# iom480ae register map
Registers are 32-bit, access not given, no defined reset value unless marked. A register's access mark holds for its fields unless they carry their own. Addresses are absolute; registers are grouped by the start of their names; [hi:lo] are bit positions.

## SC0
0x40090000 SC0_SC_DAT
  [7:0] DAT
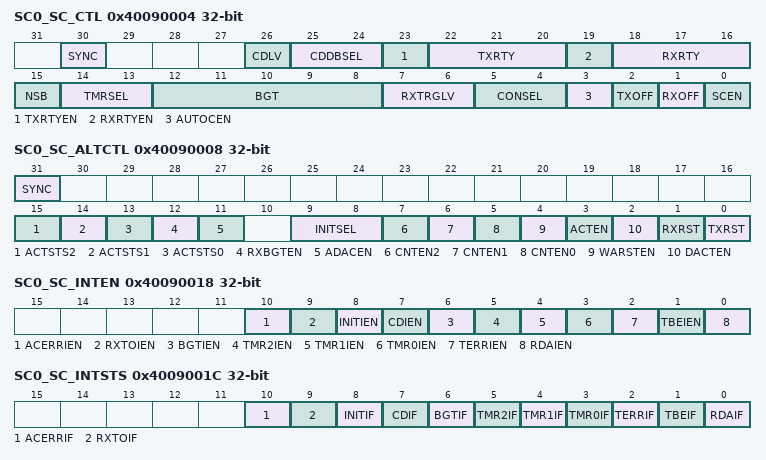
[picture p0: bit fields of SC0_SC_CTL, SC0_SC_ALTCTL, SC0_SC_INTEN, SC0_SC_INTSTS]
0x40090004 SC0_SC_CTL
  [30] SYNC, [26] CDLV, [25:24] CDDBSEL, [23] TXRTYEN, [22:20] TXRTY, [19] RXRTYEN, [18:16] RXRTY, [15] NSB, [14:13] TMRSEL, [12:8] BGT, [7:6] RXTRGLV, [5:4] CONSEL, [3] AUTOCEN, [2] TXOFF, [1] RXOFF, [0] SCEN
0x40090008 SC0_SC_ALTCTL
  [31] SYNC, [15] ACTSTS2, [14] ACTSTS1, [13] ACTSTS0, [12] RXBGTEN, [11] ADACEN, [9:8] INITSEL, [7] CNTEN2, [6] CNTEN1, [5] CNTEN0, [4] WARSTEN, [3] ACTEN, [2] DACTEN, [1] RXRST, [0] TXRST
0x4009000C SC0_SC_EGT
  [7:0] EGT
0x40090010 SC0_SC_RXTOUT
  [8:0] RFTM
0x40090014 SC0_SC_ETUCTL
  [11:0] ETURDIV
0x40090018 SC0_SC_INTEN
  [10] ACERRIEN, [9] RXTOIEN, [8] INITIEN, [7] CDIEN, [6] BGTIEN, [5] TMR2IEN, [4] TMR1IEN, [3] TMR0IEN, [2] TERRIEN, [1] TBEIEN, [0] RDAIEN
0x4009001C SC0_SC_INTSTS
  [10] ACERRIF, [9] RXTOIF, [8] INITIF, [7] CDIF, [6] BGTIF, [5] TMR2IF, [4] TMR1IF, [3] TMR0IF, [2] TERRIF, [1] TBEIF, [0] RDAIF
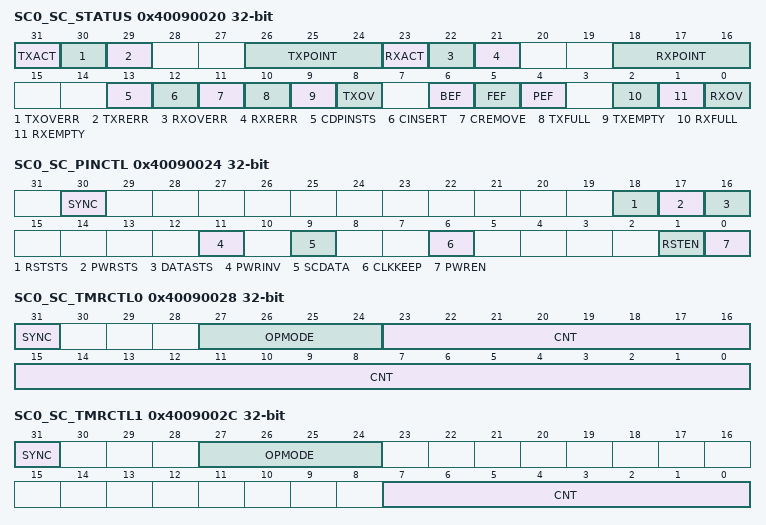
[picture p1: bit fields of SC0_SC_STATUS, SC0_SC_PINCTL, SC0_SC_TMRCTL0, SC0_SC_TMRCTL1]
0x40090020 SC0_SC_STATUS
  [31] TXACT, [30] TXOVERR, [29] TXRERR, [26:24] TXPOINT, [23] RXACT, [22] RXOVERR, [21] RXRERR, [18:16] RXPOINT, [13] CDPINSTS, [12] CINSERT, [11] CREMOVE, [10] TXFULL, [9] TXEMPTY, [8] TXOV, [6] BEF, [5] FEF, [4] PEF, [2] RXFULL, [1] RXEMPTY, [0] RXOV
0x40090024 SC0_SC_PINCTL
  [30] SYNC, [18] RSTSTS, [17] PWRSTS, [16] DATASTS, [11] PWRINV, [9] SCDATA, [6] CLKKEEP, [1] RSTEN, [0] PWREN
0x40090028 SC0_SC_TMRCTL0
  [31] SYNC, [27:24] OPMODE, [23:0] CNT
0x4009002C SC0_SC_TMRCTL1
  [31] SYNC, [27:24] OPMODE, [7:0] CNT
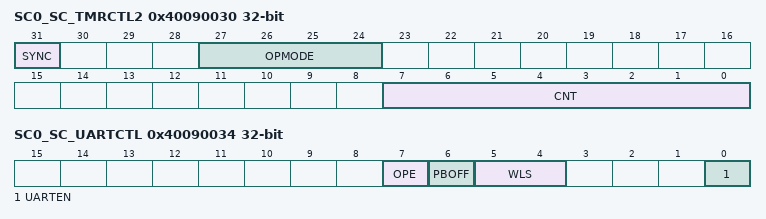
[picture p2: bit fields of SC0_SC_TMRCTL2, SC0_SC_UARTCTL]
0x40090030 SC0_SC_TMRCTL2
  [31] SYNC, [27:24] OPMODE, [7:0] CNT
0x40090034 SC0_SC_UARTCTL
  [7] OPE, [6] PBOFF, [5:4] WLS, [0] UARTEN
0x4009004C SC0_SC_ACTCTL
  [4:0] T1EXT

## SC1
0x40091000 SC1_SC_DAT
  [7:0] DAT
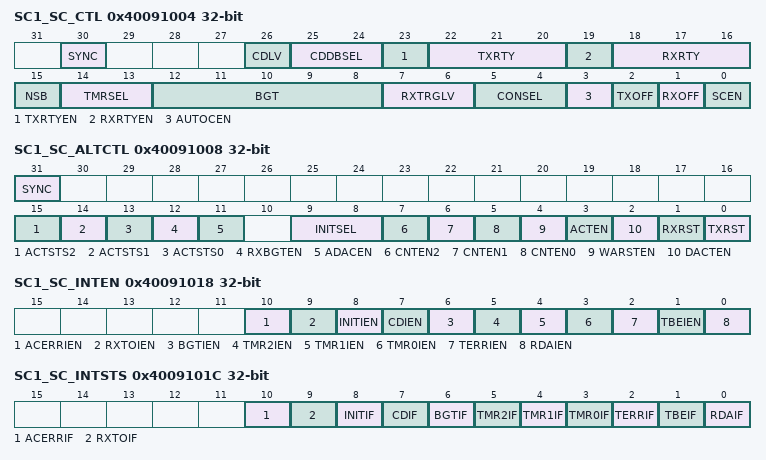
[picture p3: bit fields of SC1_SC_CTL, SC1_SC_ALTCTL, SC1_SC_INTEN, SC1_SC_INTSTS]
0x40091004 SC1_SC_CTL
  [30] SYNC, [26] CDLV, [25:24] CDDBSEL, [23] TXRTYEN, [22:20] TXRTY, [19] RXRTYEN, [18:16] RXRTY, [15] NSB, [14:13] TMRSEL, [12:8] BGT, [7:6] RXTRGLV, [5:4] CONSEL, [3] AUTOCEN, [2] TXOFF, [1] RXOFF, [0] SCEN
0x40091008 SC1_SC_ALTCTL
  [31] SYNC, [15] ACTSTS2, [14] ACTSTS1, [13] ACTSTS0, [12] RXBGTEN, [11] ADACEN, [9:8] INITSEL, [7] CNTEN2, [6] CNTEN1, [5] CNTEN0, [4] WARSTEN, [3] ACTEN, [2] DACTEN, [1] RXRST, [0] TXRST
0x4009100C SC1_SC_EGT
  [7:0] EGT
0x40091010 SC1_SC_RXTOUT
  [8:0] RFTM
0x40091014 SC1_SC_ETUCTL
  [11:0] ETURDIV
0x40091018 SC1_SC_INTEN
  [10] ACERRIEN, [9] RXTOIEN, [8] INITIEN, [7] CDIEN, [6] BGTIEN, [5] TMR2IEN, [4] TMR1IEN, [3] TMR0IEN, [2] TERRIEN, [1] TBEIEN, [0] RDAIEN
0x4009101C SC1_SC_INTSTS
  [10] ACERRIF, [9] RXTOIF, [8] INITIF, [7] CDIF, [6] BGTIF, [5] TMR2IF, [4] TMR1IF, [3] TMR0IF, [2] TERRIF, [1] TBEIF, [0] RDAIF
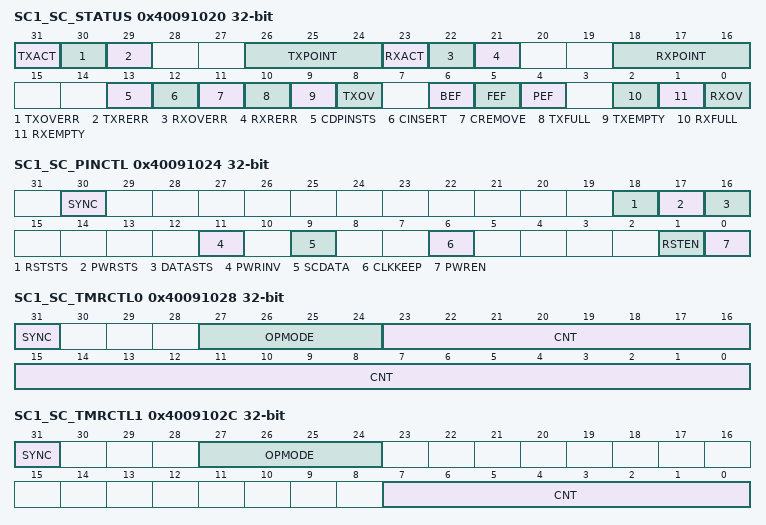
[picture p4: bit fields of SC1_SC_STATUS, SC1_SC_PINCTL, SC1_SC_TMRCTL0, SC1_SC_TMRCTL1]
0x40091020 SC1_SC_STATUS
  [31] TXACT, [30] TXOVERR, [29] TXRERR, [26:24] TXPOINT, [23] RXACT, [22] RXOVERR, [21] RXRERR, [18:16] RXPOINT, [13] CDPINSTS, [12] CINSERT, [11] CREMOVE, [10] TXFULL, [9] TXEMPTY, [8] TXOV, [6] BEF, [5] FEF, [4] PEF, [2] RXFULL, [1] RXEMPTY, [0] RXOV
0x40091024 SC1_SC_PINCTL
  [30] SYNC, [18] RSTSTS, [17] PWRSTS, [16] DATASTS, [11] PWRINV, [9] SCDATA, [6] CLKKEEP, [1] RSTEN, [0] PWREN
0x40091028 SC1_SC_TMRCTL0
  [31] SYNC, [27:24] OPMODE, [23:0] CNT
0x4009102C SC1_SC_TMRCTL1
  [31] SYNC, [27:24] OPMODE, [7:0] CNT
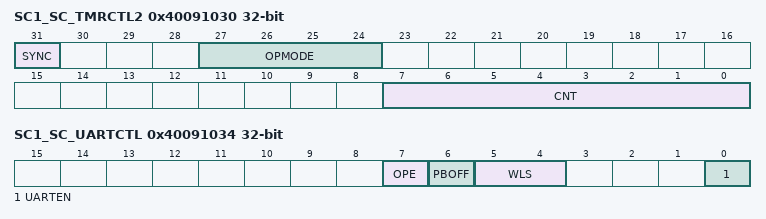
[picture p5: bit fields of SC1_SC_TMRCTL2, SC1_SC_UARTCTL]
0x40091030 SC1_SC_TMRCTL2
  [31] SYNC, [27:24] OPMODE, [7:0] CNT
0x40091034 SC1_SC_UARTCTL
  [7] OPE, [6] PBOFF, [5:4] WLS, [0] UARTEN
0x4009104C SC1_SC_ACTCTL
  [4:0] T1EXT

## SC2
0x40092000 SC2_SC_DAT
  [7:0] DAT
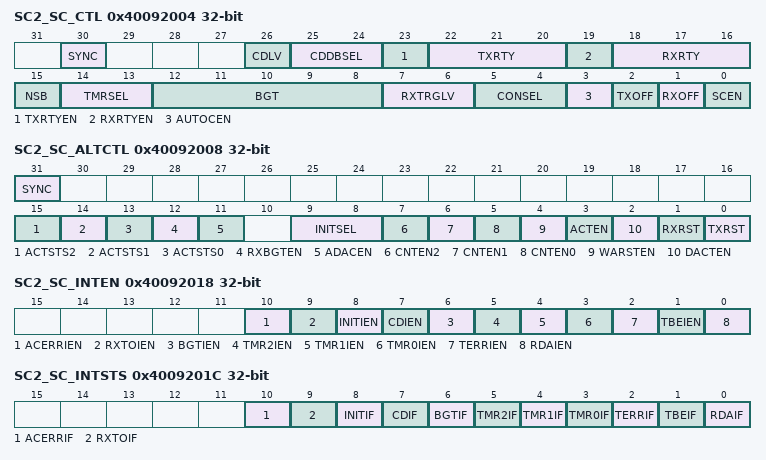
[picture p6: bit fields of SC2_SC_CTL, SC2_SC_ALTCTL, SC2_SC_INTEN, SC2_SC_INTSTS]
0x40092004 SC2_SC_CTL
  [30] SYNC, [26] CDLV, [25:24] CDDBSEL, [23] TXRTYEN, [22:20] TXRTY, [19] RXRTYEN, [18:16] RXRTY, [15] NSB, [14:13] TMRSEL, [12:8] BGT, [7:6] RXTRGLV, [5:4] CONSEL, [3] AUTOCEN, [2] TXOFF, [1] RXOFF, [0] SCEN
0x40092008 SC2_SC_ALTCTL
  [31] SYNC, [15] ACTSTS2, [14] ACTSTS1, [13] ACTSTS0, [12] RXBGTEN, [11] ADACEN, [9:8] INITSEL, [7] CNTEN2, [6] CNTEN1, [5] CNTEN0, [4] WARSTEN, [3] ACTEN, [2] DACTEN, [1] RXRST, [0] TXRST
0x4009200C SC2_SC_EGT
  [7:0] EGT
0x40092010 SC2_SC_RXTOUT
  [8:0] RFTM
0x40092014 SC2_SC_ETUCTL
  [11:0] ETURDIV
0x40092018 SC2_SC_INTEN
  [10] ACERRIEN, [9] RXTOIEN, [8] INITIEN, [7] CDIEN, [6] BGTIEN, [5] TMR2IEN, [4] TMR1IEN, [3] TMR0IEN, [2] TERRIEN, [1] TBEIEN, [0] RDAIEN
0x4009201C SC2_SC_INTSTS
  [10] ACERRIF, [9] RXTOIF, [8] INITIF, [7] CDIF, [6] BGTIF, [5] TMR2IF, [4] TMR1IF, [3] TMR0IF, [2] TERRIF, [1] TBEIF, [0] RDAIF
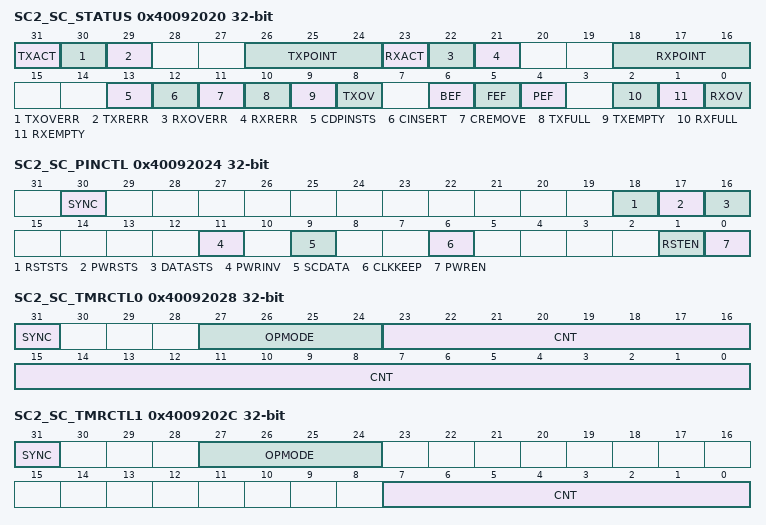
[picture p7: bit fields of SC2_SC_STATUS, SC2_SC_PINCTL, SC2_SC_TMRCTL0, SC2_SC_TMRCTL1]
0x40092020 SC2_SC_STATUS
  [31] TXACT, [30] TXOVERR, [29] TXRERR, [26:24] TXPOINT, [23] RXACT, [22] RXOVERR, [21] RXRERR, [18:16] RXPOINT, [13] CDPINSTS, [12] CINSERT, [11] CREMOVE, [10] TXFULL, [9] TXEMPTY, [8] TXOV, [6] BEF, [5] FEF, [4] PEF, [2] RXFULL, [1] RXEMPTY, [0] RXOV
0x40092024 SC2_SC_PINCTL
  [30] SYNC, [18] RSTSTS, [17] PWRSTS, [16] DATASTS, [11] PWRINV, [9] SCDATA, [6] CLKKEEP, [1] RSTEN, [0] PWREN
0x40092028 SC2_SC_TMRCTL0
  [31] SYNC, [27:24] OPMODE, [23:0] CNT
0x4009202C SC2_SC_TMRCTL1
  [31] SYNC, [27:24] OPMODE, [7:0] CNT
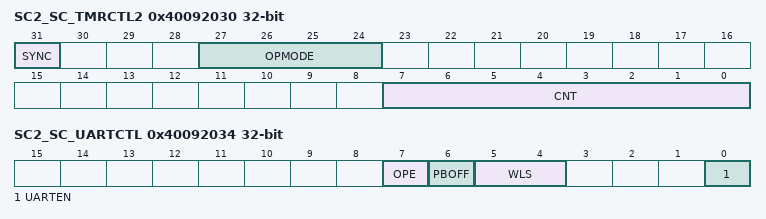
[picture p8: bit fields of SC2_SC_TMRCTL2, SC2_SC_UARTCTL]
0x40092030 SC2_SC_TMRCTL2
  [31] SYNC, [27:24] OPMODE, [7:0] CNT
0x40092034 SC2_SC_UARTCTL
  [7] OPE, [6] PBOFF, [5:4] WLS, [0] UARTEN
0x4009204C SC2_SC_ACTCTL
  [4:0] T1EXT
